# CALC3_LSE_ICONT register map
Vendor: Texas Instruments
Peripheral module from a debugger description file (folder TDA2Ex).
Registers are 32-bit, access not given, reset 0x1 unless marked. A register's access mark holds for its fields unless they carry their own. Offsets are as the file gives them; lines under a group give offsets from that group; [hi:lo] are bit positions; {n}, {i} and the like mark numbered series; 'fields as' and 'values as' point back to an identical list; <NAME> marks a mode.

## CALC3_LSE_ICONT
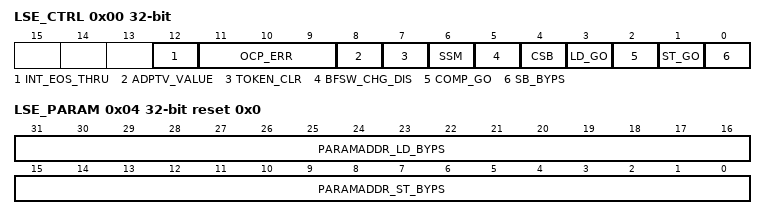
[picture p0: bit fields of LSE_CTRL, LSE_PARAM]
0x00 LSE_CTRL — Controller
  [12] INT_EOS_THRU rw — int_eos through bit 0 : LSE does the process for slice boundary after receiving int_eos. 1: int_eos is passed through to SYNCBOX_CALC3 without the process for slice boundary
  [11:9] OCP_ERR — OCP error status bit. Writing 0 is ignored. These bits remain 1 until RESET or until the host sets to 1.[11]: OCP DMA IP_CORE side . [10]: OCP DMA SL2 side . [9]: OCP CFG IP_CORE side . (access RW WSpecial)
    0=When_Sresp_is_not_ERR; 1=When_Sresp_is_ERR
  [8] ADPTV_VALUE ro — Status Adaptv_add() value This signal is cleared, if Token_clr=1.
  [7] TOKEN_CLR — LSE internal signals will be initialized to understand prologue(1st MB) as below: . -token status signal -token start/end signal -DMA pointer Writing 0 is ignored. Writing 1 clears some internal signal. This is a self-clearing bit. The host will always read 0. If this is not used for initialization at prolog, some internal signal is kept. Also, synchronization does not function well (access W WSpecial)
  [6] SSM rw — Single Step Mode
    0=Normal_Mode; 1=Enable_Single_Step_Mdde
  [5] BFSW_CHG_DIS rw — Disabled internal BFSW change
    0=LSE_BFSW_LD_0 (Enable internal bfsw change (default) Then, LSE controls BFSW after LD task finished.); 1=BFSW_BFSW_LD_GO,_COMP_GO_ST_GO.)_1 (Disable BFSW change (If host want to control BFSW with each task step by step with LD_GO, COMP_GO and ST_GO.))
  [4] CSB — Command Status Bit – These bits remain 1 until RESET or Token_clr or until the host sets to 1. (access RW WSpecial)
    0=LSE_command_is_defined; 1=LSE_1 (LSE command is undefined Writing 0 is ignored.)
  [3] LD_GO — Execute LOAD task on Byps mode Target ParamAddr_ld_byps must be set before this bit is set. This bit is cleared after LD Task finishes. (access RW WSpecial)
    0=Idle_Writing_0_is_ignored; 1=LD_LSE_LOAD_1 (Execute LD task. LSE access to ParamAddr_ld_byps and execute the command for LOAD task.)
  [2] COMP_GO — Execute Comp task on Byps mode – In the single step mode, LSE access to ParamAddr_ld_byps and execute the command for Comp task. In the normal mode, LSE executes COMP commands followed by LD commands. This bit is cleared after Comp Task finishes. (access RW WSpecial)
    0=Idle_Writing_0_is_ignored; 1=Execute_Comp_task
  [1] ST_GO — Execute Store task on Byps mode Target ParamAddr_st_byps must be set before this bit is set. This bit is cleared after ST Task finishes. (access RW WSpecial)
    0=Idle_Writing_0_is_ignored; 1=LSE_1 (Execute Store task. LSE access to ParamAddr_st_byps and execute the command for Store task.)
  [0] SB_BYPS rw — SyncBox Byps mode
    0=LSE_SYNCBOX_CALC3_0 (LSE function normal SYNCBOX_CALC3 mode and waits NewTaskSignal. This value should not change during execution.); 1=LSE_SYNCBOX_CALC3_GO_BIT._1 (LSE functions SYNCBOX_CALC3 bypass mode and executes the task of GO_BIT.)
0x04 LSE_PARAM rw reset 0x0 — Parameter address for SB Bypass mode
  [31:16] PARAMADDR_LD_BYPS — Only used in the bypass mode. Address of the first command of LD and COMP sequence (128-bit word unit). This is 128-bit word address, not byte address. The conversion from byte address to 128-bit word address should be done by CPU. IfLSE_CTRL SB_BYPS is set to 1, this value is used. In bypass mode, this address is given via this field, instead via SYNCBOX_CALC3. Also, this field is used on single-step mode.
  [15:0] PARAMADDR_ST_BYPS — Only used in the bypass mode. Address of the first command of ST sequence (128-bit word unit). This is 128-bit word address, not byte address. The conversion from byte address to 128-bit word address should be done by CPU. IfLSE_CTRL SB_BYPS is set to 1, this value is used. In bypass mode, this address is given via this field, instead via SYNCBOX_CALC3. Also, this field is used on single-step mode.
